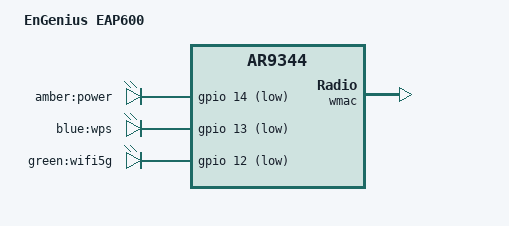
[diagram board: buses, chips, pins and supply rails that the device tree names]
// SPDX-License-Identifier: GPL-2.0-or-later OR MIT

#include "ar9344_engenius_exx600.dtsi"

/ {
	model = "EnGenius EAP600";
	compatible = "engenius,eap600", "qca,ar9344";

	leds {
		compatible = "gpio-leds";

		led_power: power {
			label = "amber:power";
			gpios = <&gpio 14 GPIO_ACTIVE_LOW>;
			default-state = "on";
		};

		wps {
			label = "blue:wps";
			gpios = <&gpio 13 GPIO_ACTIVE_LOW>;
		};

		wifi5g {
			label = "green:wifi5g";
			gpios = <&gpio 12 GPIO_ACTIVE_LOW>;
			linux,default-trigger = "phy0tpt";
		};
	};
};

&eth0 {
	nvmem-cells = <&macaddr_art_0>;
	nvmem-cell-names = "mac-address";
	mac-address-increment = <(-2)>;
};

&pcie {
	wifi@0,0,0 {
		nvmem-cells = <&macaddr_art_0>;
		nvmem-cell-names = "mac-address";
	};
};

&wmac {
	nvmem-cells = <&macaddr_art_0>;
	nvmem-cell-names = "mac-address";
	mac-address-increment = <(-1)>;
};

&art {
	compatible = "nvmem-cells";
	#address-cells = <1>;
	#size-cells = <1>;

	macaddr_art_0: macaddr@0 {
		reg = <0x0 0x6>;
	};
};
